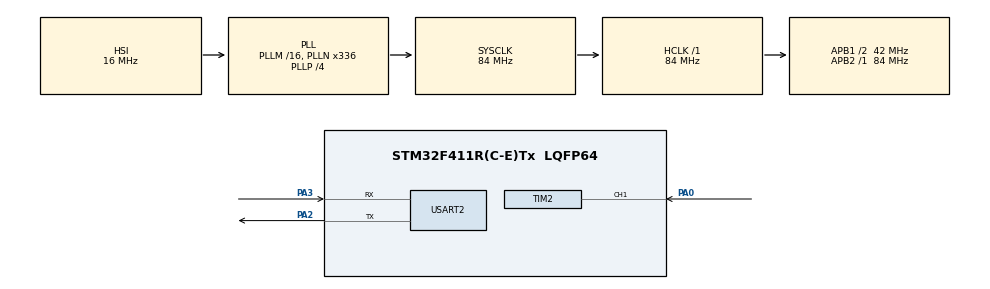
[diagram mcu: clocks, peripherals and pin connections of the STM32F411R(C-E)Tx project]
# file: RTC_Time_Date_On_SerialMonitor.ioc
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Mcu.Family=STM32F4
Mcu.Name=STM32F411R(C-E)Tx
Mcu.Package=LQFP64
NVIC.PriorityGroup=NVIC_PRIORITYGROUP_0
NVIC.TIM2_IRQn=true\:0\:0\:false\:false\:true\:true\:true\:true
PA0-WKUP.Signal=S_TIM2_CH1_ETR
PA2.Mode=Asynchronous
PA2.Signal=USART2_TX
PA3.Mode=Asynchronous
PA3.Signal=USART2_RX
ProjectManager.HeapSize=0x200
ProjectManager.StackSize=0x400
ProjectManager.TargetToolchain=STM32CubeIDE
RCC.48MHZClocksFreq_Value=84000000
RCC.AHBFreq_Value=84000000
RCC.APB1CLKDivider=RCC_HCLK_DIV2
RCC.APB1Freq_Value=42000000
RCC.APB1TimFreq_Value=84000000
RCC.APB2Freq_Value=84000000
RCC.APB2TimFreq_Value=84000000
RCC.CortexFreq_Value=84000000
RCC.FLatency-AdvancedSettings=FLASH_LATENCY_2
RCC.HCLKFreq_Value=84000000
RCC.HSE_VALUE=8000000
RCC.HSI_VALUE=16000000
RCC.LSE_VALUE=32768
RCC.PLLN=336
RCC.PLLP=RCC_PLLP_DIV4
RCC.SYSCLKFreq_VALUE=84000000
RCC.SYSCLKSource=RCC_SYSCLKSOURCE_PLLCLK
RCC.VCOOutputFreq_Value=336000000
RTC.Date=19
RTC.Hours=12
RTC.Minutes=35
RTC.Month=RTC_MONTH_OCTOBER
RTC.WeekDay=RTC_WEEKDAY_SUNDAY
RTC.Year=25
SH.S_TIM2_CH1_ETR.0=TIM2_CH1,Input_Capture1_from_TI1
TIM2.AutoReloadPreload=TIM_AUTORELOAD_PRELOAD_ENABLE
TIM2.Channel-Input_Capture1_from_TI1=TIM_CHANNEL_1
TIM2.Period=299999
TIM2.Prescaler=8399
USART2.VirtualMode=VM_ASYNC
VP_RTC_VS_RTC_Activate.Mode=RTC_Enabled
VP_RTC_VS_RTC_Calendar.Mode=RTC_Calendar
VP_TIM2_VS_ClockSourceINT.Mode=Internal
board=NUCLEO-F411RE

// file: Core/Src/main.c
/* USER CODE BEGIN Header */
/**
  ******************************************************************************
  * @file           : main.c
  * @brief          : Main program body
  ******************************************************************************
  * @attention
  *
  * Copyright (c) 2025 STMicroelectronics.
  * All rights reserved.
  *
  * This software is licensed under terms that can be found in the LICENSE file
  * in the root directory of this software component.
  * If no LICENSE file comes with this software, it is provided AS-IS.
  *
  ******************************************************************************
  */
/* USER CODE END Header */
#include "main.h"

/* USER CODE BEGIN Includes */
#include<stdio.h>
#include<string.h>
/* USER CODE END Includes */

/* USER CODE BEGIN PTD */
  char Time_buff[20];
  char Date_buff[20];
	RTC_TimeTypeDef stime;
	RTC_DateTypeDef sdate;

/* USER CODE END PTD */

RTC_HandleTypeDef hrtc;

TIM_HandleTypeDef htim2;

UART_HandleTypeDef huart2;

/* USER CODE BEGIN PV */
void HAL_TIM_PeriodElapsedCallback(TIM_HandleTypeDef *htim)

{

	        HAL_RTC_GetTime(&hrtc, &stime, RTC_FORMAT_BIN);
	        HAL_RTC_GetDate(&hrtc, &sdate, RTC_FORMAT_BIN);

	        sprintf(Time_buff, "%02d:%02d:%02d\r\n", stime.Hours, stime.Minutes, stime.Seconds);
	        sprintf(Date_buff, "%02d-%02d-20%02d\r\n", sdate.Date, sdate.Month, sdate.Year); // Optional: prefix 20 to year

	        HAL_UART_Transmit(&huart2, (uint8_t*)Time_buff, strlen(Time_buff), 200);
	        HAL_UART_Transmit(&huart2, (uint8_t*)Date_buff, strlen(Date_buff), 200);
}

/* USER CODE END PV */

void SystemClock_Config(void);
static void MX_GPIO_Init(void);
static void MX_USART2_UART_Init(void);
static void MX_RTC_Init(void);
static void MX_TIM2_Init(void);

int main(void)
{

  /* MCU Configuration--------------------------------------------------------*/

  /* Reset of all peripherals, Initializes the Flash interface and the Systick. */
  HAL_Init();

  /* Configure the system clock */
  SystemClock_Config();

  /* Initialize all configured peripherals */
  MX_GPIO_Init();
  MX_USART2_UART_Init();
  MX_RTC_Init();
  MX_TIM2_Init();
  /* USER CODE BEGIN 2 */
  TIM1->CCR1=599999;

  	  HAL_TIM_Base_Start_IT(&htim2);
  	  HAL_RTC_Init(&hrtc);
//	  HAL_RTC_GetTime(&hrtc, &stime, RTC_FORMAT_BIN);
//	  HAL_RTC_GetDate(&hrtc, &sdate, RTC_FORMAT_BIN);

//	  sprintf(Time_buff,"%02d:%02d:%02d\n",stime.Hours,stime.Minutes,stime.Seconds);
//	  sprintf(Date_buff,"%02d-%02d-%02d\n",sdate.Date,sdate.Month,sdate.Year);

  /* USER CODE END 2 */

  /* Infinite loop */
  while (1)
  {

  }
}

void SystemClock_Config(void)
{
  RCC_OscInitTypeDef RCC_OscInitStruct = {0};
  RCC_ClkInitTypeDef RCC_ClkInitStruct = {0};

  /** Configure the main internal regulator output voltage
  */
  __HAL_RCC_PWR_CLK_ENABLE();
  __HAL_PWR_VOLTAGESCALING_CONFIG(PWR_REGULATOR_VOLTAGE_SCALE1);

  /** Initializes the RCC Oscillators according to the specified parameters
  * in the RCC_OscInitTypeDef structure.
  */
  RCC_OscInitStruct.OscillatorType = RCC_OSCILLATORTYPE_HSI|RCC_OSCILLATORTYPE_LSI;
  RCC_OscInitStruct.HSIState = RCC_HSI_ON;
  RCC_OscInitStruct.HSICalibrationValue = RCC_HSICALIBRATION_DEFAULT;
  RCC_OscInitStruct.LSIState = RCC_LSI_ON;
  RCC_OscInitStruct.PLL.PLLState = RCC_PLL_ON;
  RCC_OscInitStruct.PLL.PLLSource = RCC_PLLSOURCE_HSI;
  RCC_OscInitStruct.PLL.PLLM = 16;
  RCC_OscInitStruct.PLL.PLLN = 336;
  RCC_OscInitStruct.PLL.PLLP = RCC_PLLP_DIV4;
  RCC_OscInitStruct.PLL.PLLQ = 4;
  if (HAL_RCC_OscConfig(&RCC_OscInitStruct) != HAL_OK)
  {
    Error_Handler();
  }

  /** Initializes the CPU, AHB and APB buses clocks
  */
  RCC_ClkInitStruct.ClockType = RCC_CLOCKTYPE_HCLK|RCC_CLOCKTYPE_SYSCLK
                              |RCC_CLOCKTYPE_PCLK1|RCC_CLOCKTYPE_PCLK2;
  RCC_ClkInitStruct.SYSCLKSource = RCC_SYSCLKSOURCE_PLLCLK;
  RCC_ClkInitStruct.AHBCLKDivider = RCC_SYSCLK_DIV1;
  RCC_ClkInitStruct.APB1CLKDivider = RCC_HCLK_DIV2;
  RCC_ClkInitStruct.APB2CLKDivider = RCC_HCLK_DIV1;

  if (HAL_RCC_ClockConfig(&RCC_ClkInitStruct, FLASH_LATENCY_2) != HAL_OK)
  {
    Error_Handler();
  }
}

static void MX_RTC_Init(void)
{

  RTC_TimeTypeDef sTime = {0};
  RTC_DateTypeDef sDate = {0};

  /** Initialize RTC Only
  */
  hrtc.Instance = RTC;
  hrtc.Init.HourFormat = RTC_HOURFORMAT_24;
  hrtc.Init.AsynchPrediv = 127;
  hrtc.Init.SynchPrediv = 255;
  hrtc.Init.OutPut = RTC_OUTPUT_DISABLE;
  hrtc.Init.OutPutPolarity = RTC_OUTPUT_POLARITY_HIGH;
  hrtc.Init.OutPutType = RTC_OUTPUT_TYPE_OPENDRAIN;
  if (HAL_RTC_Init(&hrtc) != HAL_OK)
  {
    Error_Handler();
  }

  /** Initialize RTC and set the Time and Date
  */
  sTime.Hours = 0x12;
  sTime.Minutes = 0x35;
  sTime.Seconds = 0x0;
  sTime.DayLightSaving = RTC_DAYLIGHTSAVING_NONE;
  sTime.StoreOperation = RTC_STOREOPERATION_RESET;
  if (HAL_RTC_SetTime(&hrtc, &sTime, RTC_FORMAT_BCD) != HAL_OK)
  {
    Error_Handler();
  }
  sDate.WeekDay = RTC_WEEKDAY_SUNDAY;
  sDate.Month = RTC_MONTH_OCTOBER;
  sDate.Date = 0x19;
  sDate.Year = 0x25;

  if (HAL_RTC_SetDate(&hrtc, &sDate, RTC_FORMAT_BCD) != HAL_OK)
  {
    Error_Handler();
  }

}

static void MX_TIM2_Init(void)
{

  TIM_ClockConfigTypeDef sClockSourceConfig = {0};
  TIM_MasterConfigTypeDef sMasterConfig = {0};
  TIM_IC_InitTypeDef sConfigIC = {0};

  htim2.Instance = TIM2;
  htim2.Init.Prescaler = 8399;
  htim2.Init.CounterMode = TIM_COUNTERMODE_UP;
  htim2.Init.Period = 299999;
  htim2.Init.ClockDivision = TIM_CLOCKDIVISION_DIV1;
  htim2.Init.AutoReloadPreload = TIM_AUTORELOAD_PRELOAD_ENABLE;
  if (HAL_TIM_Base_Init(&htim2) != HAL_OK)
  {
    Error_Handler();
  }
  sClockSourceConfig.ClockSource = TIM_CLOCKSOURCE_INTERNAL;
  if (HAL_TIM_ConfigClockSource(&htim2, &sClockSourceConfig) != HAL_OK)
  {
    Error_Handler();
  }
  if (HAL_TIM_IC_Init(&htim2) != HAL_OK)
  {
    Error_Handler();
  }
  sMasterConfig.MasterOutputTrigger = TIM_TRGO_RESET;
  sMasterConfig.MasterSlaveMode = TIM_MASTERSLAVEMODE_DISABLE;
  if (HAL_TIMEx_MasterConfigSynchronization(&htim2, &sMasterConfig) != HAL_OK)
  {
    Error_Handler();
  }
  sConfigIC.ICPolarity = TIM_INPUTCHANNELPOLARITY_RISING;
  sConfigIC.ICSelection = TIM_ICSELECTION_DIRECTTI;
  sConfigIC.ICPrescaler = TIM_ICPSC_DIV1;
  sConfigIC.ICFilter = 0;
  if (HAL_TIM_IC_ConfigChannel(&htim2, &sConfigIC, TIM_CHANNEL_1) != HAL_OK)
  {
    Error_Handler();
  }

}

static void MX_USART2_UART_Init(void)
{

  huart2.Instance = USART2;
  huart2.Init.BaudRate = 115200;
  huart2.Init.WordLength = UART_WORDLENGTH_8B;
  huart2.Init.StopBits = UART_STOPBITS_1;
  huart2.Init.Parity = UART_PARITY_NONE;
  huart2.Init.Mode = UART_MODE_TX_RX;
  huart2.Init.HwFlowCtl = UART_HWCONTROL_NONE;
  huart2.Init.OverSampling = UART_OVERSAMPLING_16;
  if (HAL_UART_Init(&huart2) != HAL_OK)
  {
    Error_Handler();
  }

}

static void MX_GPIO_Init(void)
{

  /* GPIO Ports Clock Enable */
  __HAL_RCC_GPIOA_CLK_ENABLE();

}

void Error_Handler(void)
{
  __disable_irq();
  while (1)
  {
  }
}
